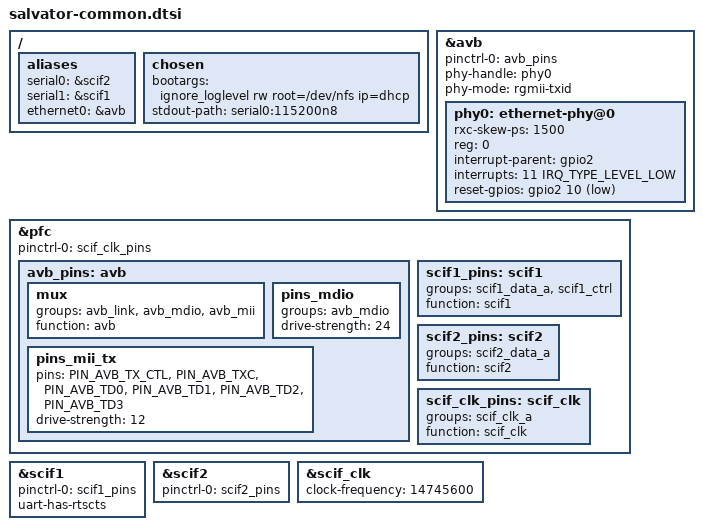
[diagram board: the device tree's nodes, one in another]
/*
 * Device Tree Source for common parts of Salvator-X board variants
 *
 * Copyright (C) 2015-2016 Renesas Electronics Corp.
 *
 * This file is licensed under the terms of the GNU General Public License
 * version 2.  This program is licensed "as is" without any warranty of any
 * kind, whether express or implied.
 */

/*
 * SSI-AK4613
 *
 * This command is required when Playback/Capture
 *
 *	amixer set "DVC Out" 100%
 *	amixer set "DVC In" 100%
 *
 * You can use Mute
 *
 *	amixer set "DVC Out Mute" on
 *	amixer set "DVC In Mute" on
 *
 * You can use Volume Ramp
 *
 *	amixer set "DVC Out Ramp Up Rate"   "0.125 dB/64 steps"
 *	amixer set "DVC Out Ramp Down Rate" "0.125 dB/512 steps"
 *	amixer set "DVC Out Ramp" on
 *	aplay xxx.wav &
 *	amixer set "DVC Out"  80%  // Volume Down
 *	amixer set "DVC Out" 100%  // Volume Up
 */

#include <dt-bindings/gpio/gpio.h>

/ {
	aliases {
		serial0 = &scif2;
		serial1 = &scif1;
		ethernet0 = &avb;
	};

	chosen {
		bootargs = "ignore_loglevel rw root=/dev/nfs ip=dhcp";
		stdout-path = "serial0:115200n8";
	};

};



&avb {
	pinctrl-0 = <&avb_pins>;
	pinctrl-names = "default";
	phy-handle = <&phy0>;
	phy-mode = "rgmii-txid";
	status = "okay";

	phy0: ethernet-phy@0 {
		rxc-skew-ps = <1500>;
		reg = <0>;
		interrupt-parent = <&gpio2>;
		interrupts = <11 IRQ_TYPE_LEVEL_LOW>;
		reset-gpios = <&gpio2 10 GPIO_ACTIVE_LOW>;
	};
};


&pfc {
	pinctrl-0 = <&scif_clk_pins>;
	pinctrl-names = "default";

	avb_pins: avb {
		mux {
			groups = "avb_link", "avb_mdio", "avb_mii";
			function = "avb";
		};

		pins_mdio {
			groups = "avb_mdio";
			drive-strength = <24>;
		};

		pins_mii_tx {
			pins = "PIN_AVB_TX_CTL", "PIN_AVB_TXC", "PIN_AVB_TD0",
			       "PIN_AVB_TD1", "PIN_AVB_TD2", "PIN_AVB_TD3";
			drive-strength = <12>;
		};
	};

	scif1_pins: scif1 {
		groups = "scif1_data_a", "scif1_ctrl";
		function = "scif1";
	};

	scif2_pins: scif2 {
		groups = "scif2_data_a";
		function = "scif2";
	};

	scif_clk_pins: scif_clk {
		groups = "scif_clk_a";
		function = "scif_clk";
	};

};


&scif1 {
	pinctrl-0 = <&scif1_pins>;
	pinctrl-names = "default";

	uart-has-rtscts;
	status = "okay";
};

&scif2 {
	pinctrl-0 = <&scif2_pins>;
	pinctrl-names = "default";

	status = "okay";
};

&scif_clk {
	clock-frequency = <14745600>;
};




